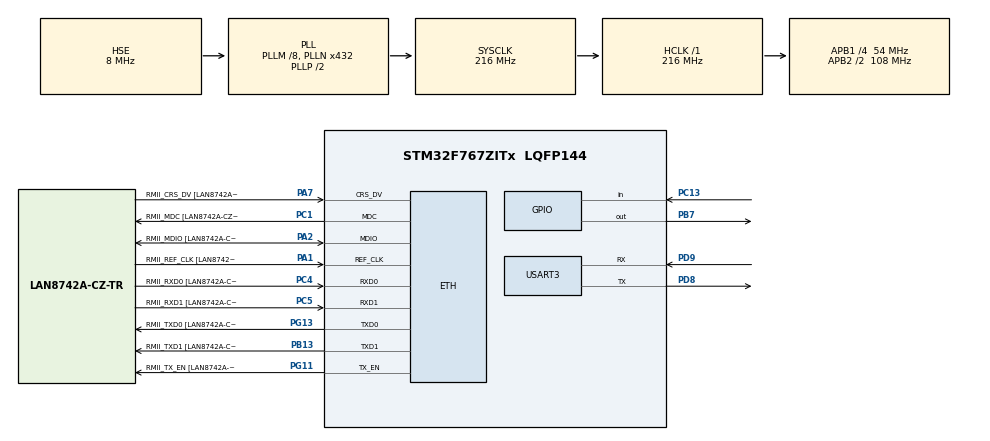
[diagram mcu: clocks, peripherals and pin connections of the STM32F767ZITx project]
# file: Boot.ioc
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ETH.MediaInterface=HAL_ETH_RMII_MODE
ETH.PhyAddress=0
Mcu.Family=STM32F7
Mcu.Name=STM32F767ZITx
Mcu.Package=LQFP144
NVIC.PriorityGroup=NVIC_PRIORITYGROUP_4
PA1.GPIO_Label=RMII_REF_CLK [LAN8742A-CZ-TR_REFCLK0]
PA1.Mode=RMII
PA1.Signal=ETH_REF_CLK
PA2.GPIO_Label=RMII_MDIO [LAN8742A-CZ-TR_MDIO]
PA2.Mode=RMII
PA2.Signal=ETH_MDIO
PA7.GPIO_Label=RMII_CRS_DV [LAN8742A-CZ-TR_CRS_DV]
PA7.Mode=RMII
PA7.Signal=ETH_CRS_DV
PB13.GPIO_Label=RMII_TXD1 [LAN8742A-CZ-TR_TXD1]
PB13.Mode=RMII
PB13.Signal=ETH_TXD1
PB7.Signal=GPIO_Output
PC1.GPIO_Label=RMII_MDC [LAN8742A-CZ-TR_MDC]
PC1.Mode=RMII
PC1.Signal=ETH_MDC
PC13.Signal=GPIO_Input
PC4.GPIO_Label=RMII_RXD0 [LAN8742A-CZ-TR_RXD0]
PC4.Mode=RMII
PC4.Signal=ETH_RXD0
PC5.GPIO_Label=RMII_RXD1 [LAN8742A-CZ-TR_RXD1]
PC5.Mode=RMII
PC5.Signal=ETH_RXD1
PD8.Mode=Asynchronous
PD8.Signal=USART3_TX
PD9.Mode=Asynchronous
PD9.Signal=USART3_RX
PG11.GPIO_Label=RMII_TX_EN [LAN8742A-CZ-TR_TXEN]
PG11.Mode=RMII
PG11.Signal=ETH_TX_EN
PG13.GPIO_Label=RMII_TXD0 [LAN8742A-CZ-TR_TXD0]
PG13.Mode=RMII
PG13.Signal=ETH_TXD0
PH0/OSC_IN.GPIO_Label=MCO [STM32F103CBT6_PA8]
PH0/OSC_IN.Mode=HSE-External-Clock-Source
PH0/OSC_IN.Signal=RCC_OSC_IN
PH1/OSC_OUT.Mode=HSE-External-Clock-Source
PH1/OSC_OUT.Signal=RCC_OSC_OUT
ProjectManager.HeapSize=0x200
ProjectManager.StackSize=0x400
ProjectManager.TargetToolchain=STM32CubeIDE
RCC.48MHZClocksFreq_Value=24000000
RCC.AHBFreq_Value=216000000
RCC.APB1CLKDivider=RCC_HCLK_DIV4
RCC.APB1Freq_Value=54000000
RCC.APB1TimFreq_Value=108000000
RCC.APB2CLKDivider=RCC_HCLK_DIV2
RCC.APB2Freq_Value=108000000
RCC.APB2TimFreq_Value=216000000
RCC.CortexFreq_Value=216000000
RCC.HCLKFreq_Value=216000000
RCC.HSE_VALUE=8000000
RCC.HSI_VALUE=16000000
RCC.LSE_VALUE=32768
RCC.PLLM=8
RCC.PLLMUL=RCC_PLL_MUL9
RCC.PLLN=432
RCC.PLLSourceVirtual=RCC_PLLSOURCE_HSE
RCC.PRESCALERUSB=RCC_USBCLKSOURCE_PLL_DIV1_5
RCC.SYSCLKFreq_VALUE=216000000
RCC.SYSCLKSource=RCC_SYSCLKSOURCE_PLLCLK
RCC.SYSCLKSourceVirtual=RCC_SYSCLKSOURCE_PLLCLK
RCC.USBFreq_Value=216000000
RCC.VCOOutputFreq_Value=432000000
USART3.VirtualMode-Asynchronous=VM_ASYNC
board=NUCLEO-F767ZI

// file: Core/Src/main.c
/* USER CODE BEGIN Header */
/**
  ******************************************************************************
  * @file           : main.c
  * @brief          : Main program body
  ******************************************************************************
  * @attention
  *
  * <h2><center>&copy; Copyright (c) 2020 STMicroelectronics.
  * All rights reserved.</center></h2>
  *
  * This software component is licensed by ST under BSD 3-Clause license,
  * the "License"; You may not use this file except in compliance with the
  * License. You may obtain a copy of the License at:
  *                        opensource.org/licenses/BSD-3-Clause
  *
  ******************************************************************************
  */
/* USER CODE END Header */
#include "main.h"
#include "string.h"

/* USER CODE BEGIN Includes */
#include "app.h"
/* USER CODE END Includes */

#if defined ( __ICCARM__ ) /*!< IAR Compiler */
#pragma location=0x2007c000
ETH_DMADescTypeDef  DMARxDscrTab[ETH_RX_DESC_CNT]; /* Ethernet Rx DMA Descriptors */
#pragma location=0x2007c0a0
ETH_DMADescTypeDef  DMATxDscrTab[ETH_TX_DESC_CNT]; /* Ethernet Tx DMA Descriptors */

#elif defined ( __CC_ARM )  /* MDK ARM Compiler */

__attribute__((at(0x2007c000))) ETH_DMADescTypeDef  DMARxDscrTab[ETH_RX_DESC_CNT]; /* Ethernet Rx DMA Descriptors */
__attribute__((at(0x2007c0a0))) ETH_DMADescTypeDef  DMATxDscrTab[ETH_TX_DESC_CNT]; /* Ethernet Tx DMA Descriptors */

#elif defined ( __GNUC__ ) /* GNU Compiler */

ETH_DMADescTypeDef DMARxDscrTab[ETH_RX_DESC_CNT] __attribute__((section(".RxDecripSection"))); /* Ethernet Rx DMA Descriptors */
ETH_DMADescTypeDef DMATxDscrTab[ETH_TX_DESC_CNT] __attribute__((section(".TxDecripSection")));   /* Ethernet Tx DMA Descriptors */
#endif

ETH_TxPacketConfig TxConfig;

ETH_HandleTypeDef heth;

void SystemClock_Config(void);
static void MX_GPIO_Init(void);
static void MX_USART3_UART_Init(void);

int main(void)
{

  /* MCU Configuration--------------------------------------------------------*/

  /* Reset of all peripherals, Initializes the Flash interface and the Systick. */
  HAL_Init();

  /* Configure the system clock */
  SystemClock_Config();

  /* Initialize all configured peripherals */
  MX_GPIO_Init();
  MX_USART3_UART_Init();
  /* USER CODE BEGIN 2 */
  /* Initialize the bootloader application. */
  AppInit();
  /* USER CODE END 2 */

  /* Infinite loop */
  /* USER CODE BEGIN WHILE */
  while (1)
  {
    /* Run the bootloader application. */
    AppTask();
    /* USER CODE END WHILE */

  }
}

void SystemClock_Config(void)
{
  RCC_OscInitTypeDef RCC_OscInitStruct = {0};
  RCC_ClkInitTypeDef RCC_ClkInitStruct = {0};

  /** Configure the main internal regulator output voltage
  */
  __HAL_RCC_PWR_CLK_ENABLE();
  __HAL_PWR_VOLTAGESCALING_CONFIG(PWR_REGULATOR_VOLTAGE_SCALE1);

  /** Initializes the RCC Oscillators according to the specified parameters
  * in the RCC_OscInitTypeDef structure.
  */
  RCC_OscInitStruct.OscillatorType = RCC_OSCILLATORTYPE_HSE;
  RCC_OscInitStruct.HSEState = RCC_HSE_BYPASS;
  RCC_OscInitStruct.PLL.PLLState = RCC_PLL_ON;
  RCC_OscInitStruct.PLL.PLLSource = RCC_PLLSOURCE_HSE;
  RCC_OscInitStruct.PLL.PLLM = 8;
  RCC_OscInitStruct.PLL.PLLN = 432;
  RCC_OscInitStruct.PLL.PLLP = RCC_PLLP_DIV2;
  RCC_OscInitStruct.PLL.PLLQ = 2;
  RCC_OscInitStruct.PLL.PLLR = 2;
  if (HAL_RCC_OscConfig(&RCC_OscInitStruct) != HAL_OK)
  {
    Error_Handler();
  }

  /** Activate the Over-Drive mode
  */
  if (HAL_PWREx_EnableOverDrive() != HAL_OK)
  {
    Error_Handler();
  }

  /** Initializes the CPU, AHB and APB buses clocks
  */
  RCC_ClkInitStruct.ClockType = RCC_CLOCKTYPE_HCLK|RCC_CLOCKTYPE_SYSCLK
                              |RCC_CLOCKTYPE_PCLK1|RCC_CLOCKTYPE_PCLK2;
  RCC_ClkInitStruct.SYSCLKSource = RCC_SYSCLKSOURCE_PLLCLK;
  RCC_ClkInitStruct.AHBCLKDivider = RCC_SYSCLK_DIV1;
  RCC_ClkInitStruct.APB1CLKDivider = RCC_HCLK_DIV4;
  RCC_ClkInitStruct.APB2CLKDivider = RCC_HCLK_DIV2;

  if (HAL_RCC_ClockConfig(&RCC_ClkInitStruct, FLASH_LATENCY_7) != HAL_OK)
  {
    Error_Handler();
  }
}

void MX_ETH_Init(void)
{

  /* USER CODE BEGIN ETH_Init 0 */
  /* Note that this function is generated but not actually used. The bootloader handles
   * the Ethernet initialization.
   */
  /* USER CODE END ETH_Init 0 */

   static uint8_t MACAddr[6];

  heth.Instance = ETH;
  MACAddr[0] = 0x00;
  MACAddr[1] = 0x80;
  MACAddr[2] = 0xE1;
  MACAddr[3] = 0x00;
  MACAddr[4] = 0x00;
  MACAddr[5] = 0x00;
  heth.Init.MACAddr = &MACAddr[0];
  heth.Init.MediaInterface = HAL_ETH_RMII_MODE;
  heth.Init.TxDesc = DMATxDscrTab;
  heth.Init.RxDesc = DMARxDscrTab;
  heth.Init.RxBuffLen = 1524;

  if (HAL_ETH_Init(&heth) != HAL_OK)
  {
    Error_Handler();
  }

  memset(&TxConfig, 0 , sizeof(ETH_TxPacketConfig));
  TxConfig.Attributes = ETH_TX_PACKETS_FEATURES_CSUM | ETH_TX_PACKETS_FEATURES_CRCPAD;
  TxConfig.ChecksumCtrl = ETH_CHECKSUM_IPHDR_PAYLOAD_INSERT_PHDR_CALC;
  TxConfig.CRCPadCtrl = ETH_CRC_PAD_INSERT;

}

static void MX_USART3_UART_Init(void)
{

  LL_USART_InitTypeDef USART_InitStruct = {0};

  LL_GPIO_InitTypeDef GPIO_InitStruct = {0};
  RCC_PeriphCLKInitTypeDef PeriphClkInitStruct = {0};

  /** Initializes the peripherals clock
  */
  PeriphClkInitStruct.PeriphClockSelection = RCC_PERIPHCLK_USART3;
  PeriphClkInitStruct.Usart3ClockSelection = RCC_USART3CLKSOURCE_PCLK1;
  if (HAL_RCCEx_PeriphCLKConfig(&PeriphClkInitStruct) != HAL_OK)
  {
    Error_Handler();
  }

  /* Peripheral clock enable */
  LL_APB1_GRP1_EnableClock(LL_APB1_GRP1_PERIPH_USART3);

  LL_AHB1_GRP1_EnableClock(LL_AHB1_GRP1_PERIPH_GPIOD);
  /**USART3 GPIO Configuration
  PD8   ------> USART3_TX
  PD9   ------> USART3_RX
  */
  GPIO_InitStruct.Pin = LL_GPIO_PIN_8;
  GPIO_InitStruct.Mode = LL_GPIO_MODE_ALTERNATE;
  GPIO_InitStruct.Speed = LL_GPIO_SPEED_FREQ_VERY_HIGH;
  GPIO_InitStruct.OutputType = LL_GPIO_OUTPUT_PUSHPULL;
  GPIO_InitStruct.Pull = LL_GPIO_PULL_NO;
  GPIO_InitStruct.Alternate = LL_GPIO_AF_7;
  LL_GPIO_Init(GPIOD, &GPIO_InitStruct);

  GPIO_InitStruct.Pin = LL_GPIO_PIN_9;
  GPIO_InitStruct.Mode = LL_GPIO_MODE_ALTERNATE;
  GPIO_InitStruct.Speed = LL_GPIO_SPEED_FREQ_VERY_HIGH;
  GPIO_InitStruct.OutputType = LL_GPIO_OUTPUT_PUSHPULL;
  GPIO_InitStruct.Pull = LL_GPIO_PULL_NO;
  GPIO_InitStruct.Alternate = LL_GPIO_AF_7;
  LL_GPIO_Init(GPIOD, &GPIO_InitStruct);

  /* USER CODE BEGIN USART3_Init 1 */
  /* Note that the USART initialization that follows here is don't care. It is
   * reconfigured upon bootloader initialization with function Rs232Init().
   */
  /* USER CODE END USART3_Init 1 */
  USART_InitStruct.BaudRate = 115200;
  USART_InitStruct.DataWidth = LL_USART_DATAWIDTH_8B;
  USART_InitStruct.StopBits = LL_USART_STOPBITS_1;
  USART_InitStruct.Parity = LL_USART_PARITY_NONE;
  USART_InitStruct.TransferDirection = LL_USART_DIRECTION_TX_RX;
  USART_InitStruct.HardwareFlowControl = LL_USART_HWCONTROL_NONE;
  USART_InitStruct.OverSampling = LL_USART_OVERSAMPLING_16;
  LL_USART_Init(USART3, &USART_InitStruct);
  LL_USART_ConfigAsyncMode(USART3);
  LL_USART_Enable(USART3);

}

static void MX_GPIO_Init(void)
{
  GPIO_InitTypeDef GPIO_InitStruct = {0};

  /* GPIO Ports Clock Enable */
  __HAL_RCC_GPIOC_CLK_ENABLE();
  __HAL_RCC_GPIOH_CLK_ENABLE();
  __HAL_RCC_GPIOA_CLK_ENABLE();
  __HAL_RCC_GPIOB_CLK_ENABLE();
  __HAL_RCC_GPIOD_CLK_ENABLE();
  __HAL_RCC_GPIOG_CLK_ENABLE();

  /*Configure GPIO pin Output Level */
  HAL_GPIO_WritePin(GPIOB, GPIO_PIN_7, GPIO_PIN_RESET);

  /*Configure GPIO pin : PC13 */
  GPIO_InitStruct.Pin = GPIO_PIN_13;
  GPIO_InitStruct.Mode = GPIO_MODE_INPUT;
  GPIO_InitStruct.Pull = GPIO_NOPULL;
  HAL_GPIO_Init(GPIOC, &GPIO_InitStruct);

  /*Configure GPIO pin : PB7 */
  GPIO_InitStruct.Pin = GPIO_PIN_7;
  GPIO_InitStruct.Mode = GPIO_MODE_OUTPUT_PP;
  GPIO_InitStruct.Pull = GPIO_NOPULL;
  GPIO_InitStruct.Speed = GPIO_SPEED_FREQ_LOW;
  HAL_GPIO_Init(GPIOB, &GPIO_InitStruct);

}

void Error_Handler(void)
{
}
